# CC1314R10 register map
File version: 1.0
CPU: CM33 1.0, other endian, MPU, FPU, 3 interrupt priority bits
Registers are 32-bit, read-write, reset 0x0 unless marked. A register's access mark holds for its fields unless they carry their own. Offsets are from the block's base; [hi:lo] are bit positions; {n}, {i} and the like mark numbered series; <NAME> marks a mode.

## UART0 — Universal Asynchronous Receiver/Transmitter (UART) interface
Base 0x40001000
Same registers: UART1 0x4000B000, UART2 0x4000C000, UART3 0x4000D000
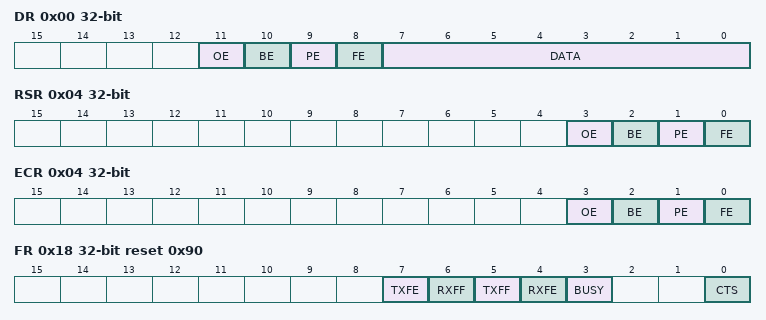
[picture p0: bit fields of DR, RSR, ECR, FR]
0x00 DR — Data For words to be transmitted: - if the FIFOs are enabled (LCRH.FEN = 1), data written to this location is pushed onto the transmit FIFO - if the FIFOs are not enabled (LCRH.FEN = 0), data is stored in the transmitter holding register (the bottom word of the transmit FIFO). The write operation initiates transmission from the UART. The data is prefixed with a start bit, appended with the appropriate parity bit (if parity is enabled), and a stop bit. The resultant word is then transmitted. For received words: - if the FIFOs are enabled (LCRH.FEN = 1), the data byte and the 4-bit status (break, frame, parity, and overrun) is pushed onto the 12-bit wide receive FIFO - if the FIFOs are not enabled (LCRH.FEN = 0), the data byte and status are stored in the receiving holding register (the bottom word of the receive FIFO). The received data byte is read by performing reads from this register along with the corresponding status information. The status information can also be read by a read of the RSR register.
  [11] OE ro — [11:11] UART Overrun Error: This bit is set to 1 if data is received and the receive FIFO is already full. The FIFO contents remain valid because no more data is written when the FIFO is full, , only the contents of the shift register are overwritten. This is cleared to 0 once there is an empty space in the FIFO and a new character can be written to it.
  [10] BE ro — [10:10] UART Break Error: This bit is set to 1 if a break condition was detected, indicating that the received data input (UARTRXD input pin) was held LOW for longer than a full-word transmission time (defined as start, data, parity and stop bits). In FIFO mode, this error is associated with the character at the top of the FIFO (that is., the oldest received data character since last read). When a break occurs, a 0 character is loaded into the FIFO. The next character is enabled after the receive data input (UARTRXD input pin) goes to a 1 (marking state), and the next valid start bit is received.
  [9] PE ro — [9:9] UART Parity Error: When set to 1, it indicates that the parity of the received data character does not match the parity that the LCRH.EPS and LCRH.SPS select. In FIFO mode, this error is associated with the character at the top of the FIFO (that is, the oldest received data character since last read).
  [8] FE ro — [8:8] UART Framing Error: When set to 1, it indicates that the received character did not have a valid stop bit (a valid stop bit is 1). In FIFO mode, this error is associated with the character at the top of the FIFO (that is., the oldest received data character since last read).
  [7:0] DATA — [7:0] Data transmitted or received: On writes, the transmit data character is pushed into the FIFO. On reads, the oldest received data character since the last read is returned.
0x04 RSR — Status This register is mapped to the same address as ECR register. Reads from this address are associated with RSR register and return the receive status. Writes to this address are associated with ECR register and clear the receive status flags (framing, parity, break, and overrun errors). If the status is read from this register, then the status information for break, framing and parity corresponds to the data character read from the Data Register, DR prior to reading the RSR. The status information for overrun is set immediately when an overrun condition occurs.
  [3] OE ro — [3:3] UART Overrun Error: This bit is set to 1 if data is received and the receive FIFO is already full. The FIFO contents remain valid because no more data is written when the FIFO is full, , only the contents of the shift register are overwritten. This is cleared to 0 once there is an empty space in the FIFO and a new character can be written to it.
  [2] BE ro — [2:2] UART Break Error: This bit is set to 1 if a break condition was detected, indicating that the received data input (UARTRXD input pin) was held LOW for longer than a full-word transmission time (defined as start, data, parity and stop bits). When a break occurs, a 0 character is loaded into the FIFO. The next character is enabled after the receive data input (UARTRXD input pin) goes to a 1 (marking state), and the next valid start bit is received.
  [1] PE ro — [1:1] UART Parity Error: When set to 1, it indicates that the parity of the received data character does not match the parity that the LCRH.EPS and LCRH.SPS select.
  [0] FE ro — [0:0] UART Framing Error: When set to 1, it indicates that the received character did not have a valid stop bit (a valid stop bit is 1).
0x04 ECR — Error Clear This register is mapped to the same address as RSR register. Reads from this address are associated with RSR register and return the receive status. Writes to this address are associated with ECR register and clear the receive status flags (framing, parity, break, and overrun errors).
  [3] OE wo — [3:3] The framing (FE), parity (PE), break (BE) and overrun (OE) errors are cleared to 0 by any write to this register.
  [2] BE wo — [2:2] The framing (FE), parity (PE), break (BE) and overrun (OE) errors are cleared to 0 by any write to this register.
  [1] PE wo — [1:1] The framing (FE), parity (PE), break (BE) and overrun (OE) errors are cleared to 0 by any write to this register.
  [0] FE wo — [0:0] The framing (FE), parity (PE), break (BE) and overrun (OE) errors are cleared to 0 by any write to this register.
0x18 FR reset 0x90 — Flag Reads from this register return the UART flags.
  [7] TXFE ro — [7:7] UART Transmit FIFO Empty: The meaning of this bit depends on the state of LCRH.FEN . - If the FIFO is disabled, this bit is set when the transmit holding register is empty. - If the FIFO is enabled, this bit is set when the transmit FIFO is empty. This bit does not indicate if there is data in the transmit shift register.
  [6] RXFF ro — [6:6] UART Receive FIFO Full: The meaning of this bit depends on the state of LCRH.FEN. - If the FIFO is disabled, this bit is set when the receive holding register is full. - If the FIFO is enabled, this bit is set when the receive FIFO is full.
  [5] TXFF ro — [5:5] UART Transmit FIFO Full: Transmit FIFO full. The meaning of this bit depends on the state of LCRH.FEN. - If the FIFO is disabled, this bit is set when the transmit holding register is full. - If the FIFO is enabled, this bit is set when the transmit FIFO is full.
  [4] RXFE ro — [4:4] UART Receive FIFO Empty: Receive FIFO empty. The meaning of this bit depends on the state of LCRH.FEN. - If the FIFO is disabled, this bit is set when the receive holding register is empty. - If the FIFO is enabled, this bit is set when the receive FIFO is empty.
  [3] BUSY ro — [3:3] UART Busy: If this bit is set to 1, the UART is busy transmitting data. This bit remains set until the complete byte, including all the stop bits, has been sent from the shift register. This bit is set as soon as the transmit FIFO becomes non-empty, regardless of whether the UART is enabled or not.
  [0] CTS ro — [0:0] Clear To Send: This bit is the complement of the active-low UART CTS input pin. That is, the bit is 1 when CTS input pin is LOW.
0x24 IBRD — Integer Baud-Rate Divisor If this register is modified while transmission or reception is on-going, the baud rate will not be updated until transmission or reception of the current character is complete.
  [15:0] DIVINT — [15:0] The integer baud rate divisor: The baud rate divisor is calculated using the formula below: Baud rate divisor = (UART reference clock frequency) / (16 * Baud rate) Baud rate divisor must be minimum 1 and maximum 65535. That is, DIVINT=0 does not give a valid baud rate. Similarly, if DIVINT=0xFFFF, any non-zero values in FBRD.DIVFRAC will be illegal. A valid value must be written to this field before the UART can be used for RX or TX operations.
0x28 FBRD — Fractional Baud-Rate Divisor If this register is modified while trasmission or reception is on-going, the baudrate will not be updated until transmission or reception of the current character is complete.
  [5:0] DIVFRAC — [5:0] Fractional Baud-Rate Divisor: The baud rate divisor is calculated using the formula below: Baud rate divisor = (UART reference clock frequency) / (16 * Baud rate) Baud rate divisor must be minimum 1 and maximum 65535. That is, IBRD.DIVINT=0 does not give a valid baud rate. Similarly, if IBRD.DIVINT=0xFFFF, any non-zero values in DIVFRAC will be illegal. A valid value must be written to this field before the UART can be used for RX or TX operations.
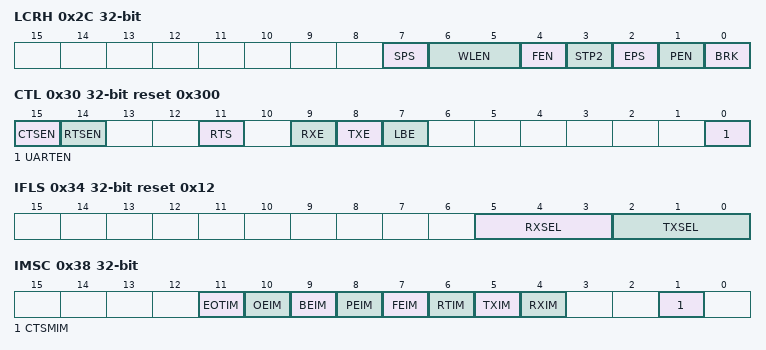
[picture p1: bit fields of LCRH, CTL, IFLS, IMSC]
0x2C LCRH — Line Control
  [7] SPS — [7:7] UART Stick Parity Select: 0: Stick parity is disabled 1: The parity bit is transmitted and checked as invert of EPS field (i.e. the parity bit is transmitted and checked as 1 when EPS = 0). This bit has no effect when PEN disables parity checking and generation.
  [6:5] WLEN — [6:5] UART Word Length: These bits indicate the number of data bits transmitted or received in a frame.
    {v}=Word Length {v+5} bits (v=0..3)
  [4] FEN — [4:4] UART Enable FIFOs
    1=EN (Transmit and receive FIFO buffers are enabled (FIFO mode)); 0=DIS (FIFOs are disabled (character mode) that is, the FIFOs become 1-byte-deep holding registers.)
  [3] STP2 — [3:3] UART Two Stop Bits Select: If this bit is set to 1, two stop bits are transmitted at the end of the frame. The receive logic does not check for two stop bits being received.
  [2] EPS — [2:2] UART Even Parity Select
    1=EVEN (Even parity: The UART generates or checks for an even number of 1s in the data and parity bits.); 0=ODD (Odd parity: The UART generates or checks for an odd number of 1s in the data and parity bits.)
  [1] PEN — [1:1] UART Parity Enable This bit controls generation and checking of parity bit.
    1=EN (Parity checking and generation is enabled.); 0=DIS (Parity is disabled and no parity bit is added to the data frame)
  [0] BRK — [0:0] UART Send Break If this bit is set to 1, a low-level is continually output on the UARTTXD output pin, after completing transmission of the current character. For the proper execution of the break command, the software must set this bit for at least two complete frames. For normal use, this bit must be cleared to 0.
0x30 CTL reset 0x300 — Control
  [15] CTSEN — [15:15] CTS hardware flow control enable
    1=EN (CTS hardware flow control enabled); 0=DIS (CTS hardware flow control disabled)
  [14] RTSEN — [14:14] RTS hardware flow control enable
    1=EN (RTS hardware flow control enabled); 0=DIS (RTS hardware flow control disabled)
  [11] RTS — [11:11] Request to Send This bit is the complement of the active-low UART RTS output. That is, when the bit is programmed to a 1 then RTS output on the pins is LOW.
  [9] RXE — [9:9] UART Receive Enable If the UART is disabled in the middle of reception, it completes the current character before stopping.
    1=EN (UART Receive enabled); 0=DIS (UART Receive disabled)
  [8] TXE — [8:8] UART Transmit Enable If the UART is disabled in the middle of transmission, it completes the current character before stopping.
    1=EN (UART Transmit enabled); 0=DIS (UART Transmit disabled)
  [7] LBE — [7:7] UART Loop Back Enable: Enabling the loop-back mode connects the UARTTXD output from the UART to UARTRXD input of the UART.
    1=EN (Loop Back enabled); 0=DIS (Loop Back disabled)
  [0] UARTEN — [0:0] UART Enable
    1=EN (UART enabled); 0=DIS (UART disabled)
0x34 IFLS reset 0x12 — Interrupt FIFO Level Select
  [5:3] RXSEL — [5:3] Receive interrupt FIFO level select: This field sets the trigger points for the receive interrupt. Values 0b101-0b111 are reserved.
    4=7_8 (Receive FIFO becomes >= 7/8 full); 3=6_8 (Receive FIFO becomes >= 3/4 full); 2=4_8 (Receive FIFO becomes >= 1/2 full); 1=2_8 (Receive FIFO becomes >= 1/4 full); 0=1_8 (Receive FIFO becomes >= 1/8 full)
  [2:0] TXSEL — [2:0] Transmit interrupt FIFO level select: This field sets the trigger points for the transmit interrupt. Values 0b101-0b111 are reserved.
    4=7_8 (Transmit FIFO becomes <= 7/8 full); 3=6_8 (Transmit FIFO becomes <= 3/4 full); 2=4_8 (Transmit FIFO becomes <= 1/2 full); 1=2_8 (Transmit FIFO becomes <= 1/4 full); 0=1_8 (Transmit FIFO becomes <= 1/8 full)
0x38 IMSC — Interrupt Mask Set/Clear
  [11] EOTIM — [11:11] End of Transmission interrupt mask. A read returns the current mask for UART's EoT interrupt. On a write of 1, the mask of the EoT interrupt is set which means the interrupt state will be reflected in MIS.EOTMIS. A write of 0 clears the mask which means MIS.EOTMIS will not reflect the interrupt.
  [10] OEIM — [10:10] Overrun error interrupt mask. A read returns the current mask for UART's overrun error interrupt. On a write of 1, the mask of the overrun error interrupt is set which means the interrupt state will be reflected in MIS.OEMIS. A write of 0 clears the mask which means MIS.OEMIS will not reflect the interrupt.
  [9] BEIM — [9:9] Break error interrupt mask. A read returns the current mask for UART's break error interrupt. On a write of 1, the mask of the overrun error interrupt is set which means the interrupt state will be reflected in MIS.BEMIS. A write of 0 clears the mask which means MIS.BEMIS will not reflect the interrupt.
  [8] PEIM — [8:8] Parity error interrupt mask. A read returns the current mask for UART's parity error interrupt. On a write of 1, the mask of the overrun error interrupt is set which means the interrupt state will be reflected in MIS.PEMIS. A write of 0 clears the mask which means MIS.PEMIS will not reflect the interrupt.
  [7] FEIM — [7:7] Framing error interrupt mask. A read returns the current mask for UART's framing error interrupt. On a write of 1, the mask of the overrun error interrupt is set which means the interrupt state will be reflected in MIS.FEMIS. A write of 0 clears the mask which means MIS.FEMIS will not reflect the interrupt.
  [6] RTIM — [6:6] Receive timeout interrupt mask. A read returns the current mask for UART's receive timeout interrupt. On a write of 1, the mask of the overrun error interrupt is set which means the interrupt state will be reflected in MIS.RTMIS. A write of 0 clears the mask which means this bitfield will not reflect the interrupt. The raw interrupt for receive timeout RIS.RTRIS cannot be set unless the mask is set (RTIM = 1). This is because the mask acts as an enable for power saving. That is, the same status can be read from MIS.RTMIS and RIS.RTRIS.
  [5] TXIM — [5:5] Transmit interrupt mask. A read returns the current mask for UART's transmit interrupt. On a write of 1, the mask of the overrun error interrupt is set which means the interrupt state will be reflected in MIS.TXMIS. A write of 0 clears the mask which means MIS.TXMIS will not reflect the interrupt.
  [4] RXIM — [4:4] Receive interrupt mask. A read returns the current mask for UART's receive interrupt. On a write of 1, the mask of the overrun error interrupt is set which means the interrupt state will be reflected in MIS.RXMIS. A write of 0 clears the mask which means MIS.RXMIS will not reflect the interrupt.
  [1] CTSMIM — [1:1] Clear to Send (CTS) modem interrupt mask. A read returns the current mask for UART's clear to send interrupt. On a write of 1, the mask of the overrun error interrupt is set which means the interrupt state will be reflected in MIS.CTSMMIS. A write of 0 clears the mask which means MIS.CTSMMIS will not reflect the interrupt.
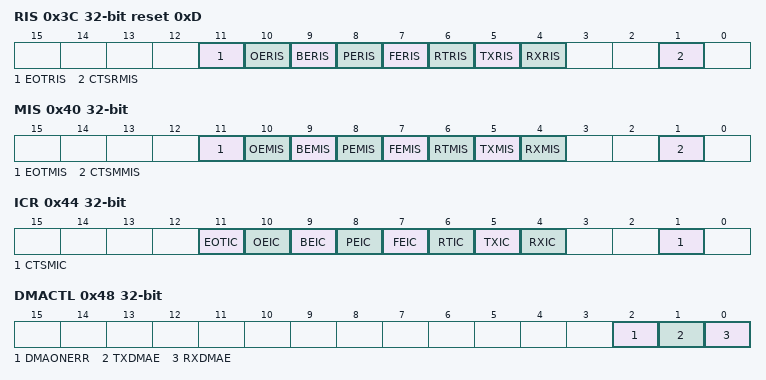
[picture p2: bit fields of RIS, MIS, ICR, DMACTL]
0x3C RIS reset 0xD — Raw Interrupt Status
  [11] EOTRIS ro — [11:11] End of Transmission interrupt status: This field returns the raw interrupt state of UART's end of transmission interrupt. End of transmission flag is set when all the Transmit data in the FIFO and on the TX Line is tranmitted.
  [10] OERIS ro — [10:10] Overrun error interrupt status: This field returns the raw interrupt state of UART's overrun error interrupt. Overrun error occurs if data is received and the receive FIFO is full.
  [9] BERIS ro — [9:9] Break error interrupt status: This field returns the raw interrupt state of UART's break error interrupt. Break error is set when a break condition is detected, indicating that the received data input (UARTRXD input pin) was held LOW for longer than a full-word transmission time (defined as start, data, parity and stop bits).
  [8] PERIS ro — [8:8] Parity error interrupt status: This field returns the raw interrupt state of UART's parity error interrupt. Parity error is set if the parity of the received data character does not match the parity that the LCRH.EPS and LCRH.SPS select.
  [7] FERIS ro — [7:7] Framing error interrupt status: This field returns the raw interrupt state of UART's framing error interrupt. Framing error is set if the received character does not have a valid stop bit (a valid stop bit is 1).
  [6] RTRIS ro — [6:6] Receive timeout interrupt status: This field returns the raw interrupt state of UART's receive timeout interrupt. The receive timeout interrupt is asserted when the receive FIFO is not empty, and no more data is received during a 32-bit period. The receive timeout interrupt is cleared either when the FIFO becomes empty through reading all the data, or when a 1 is written to ICR.RTIC. The raw interrupt for receive timeout cannot be set unless the mask is set (IMSC.RTIM = 1). This is because the mask acts as an enable for power saving. That is, the same status can be read from MIS.RTMIS and RTRIS.
  [5] TXRIS ro — [5:5] Transmit interrupt status: This field returns the raw interrupt state of UART's transmit interrupt. When FIFOs are enabled (LCRH.FEN = 1), the transmit interrupt is asserted if the number of bytes in transmit FIFO is equal to or lower than the programmed trigger level (IFLS.TXSEL). The transmit interrupt is cleared by writing data to the transmit FIFO until it becomes greater than the trigger level, or by clearing the interrupt through ICR.TXIC. When FIFOs are disabled (LCRH.FEN = 0), that is they have a depth of one location, the transmit interrupt is asserted if there is no data present in the transmitters single location. It is cleared by performing a single write to the transmit FIFO, or by clearing the interrupt through ICR.TXIC.
  [4] RXRIS ro — [4:4] Receive interrupt status: This field returns the raw interrupt state of UART's receive interrupt. When FIFOs are enabled (LCRH.FEN = 1), the receive interrupt is asserted if the receive FIFO reaches the programmed trigger level (IFLS.RXSEL). The receive interrupt is cleared by reading data from the receive FIFO until it becomes less than the trigger level, or by clearing the interrupt through ICR.RXIC. When FIFOs are disabled (LCRH.FEN = 0), that is they have a depth of one location, the receive interrupt is asserted if data is received thereby filling the location. The receive interrupt is cleared by performing a single read of the receive FIFO, or by clearing the interrupt through ICR.RXIC.
  [1] CTSRMIS ro — [1:1] Clear to Send (CTS) modem interrupt status: This field returns the raw interrupt state of UART's clear to send interrupt.
0x40 MIS — Masked Interrupt Status
  [11] EOTMIS ro — [11:11] End of Transmission interrupt status: This field returns the masked interrupt state of the overrun interrupt which is the AND product of raw interrupt state RIS.EOTRIS and the mask setting IMSC.EOTIM.
  [10] OEMIS ro — [10:10] Overrun error masked interrupt status: This field returns the masked interrupt state of the overrun interrupt which is the AND product of raw interrupt state RIS.OERIS and the mask setting IMSC.OEIM.
  [9] BEMIS ro — [9:9] Break error masked interrupt status: This field returns the masked interrupt state of the break error interrupt which is the AND product of raw interrupt state RIS.BERIS and the mask setting IMSC.BEIM.
  [8] PEMIS ro — [8:8] Parity error masked interrupt status: This field returns the masked interrupt state of the parity error interrupt which is the AND product of raw interrupt state RIS.PERIS and the mask setting IMSC.PEIM.
  [7] FEMIS ro — [7:7] Framing error masked interrupt status: Returns the masked interrupt state of the framing error interrupt which is the AND product of raw interrupt state RIS.FERIS and the mask setting IMSC.FEIM.
  [6] RTMIS ro — [6:6] Receive timeout masked interrupt status: Returns the masked interrupt state of the receive timeout interrupt. The raw interrupt for receive timeout cannot be set unless the mask is set (IMSC.RTIM = 1). This is because the mask acts as an enable for power saving. That is, the same status can be read from RTMIS and RIS.RTRIS.
  [5] TXMIS ro — [5:5] Transmit masked interrupt status: This field returns the masked interrupt state of the transmit interrupt which is the AND product of raw interrupt state RIS.TXRIS and the mask setting IMSC.TXIM.
  [4] RXMIS ro — [4:4] Receive masked interrupt status: This field returns the masked interrupt state of the receive interrupt which is the AND product of raw interrupt state RIS.RXRIS and the mask setting IMSC.RXIM.
  [1] CTSMMIS ro — [1:1] Clear to Send (CTS) modem masked interrupt status: This field returns the masked interrupt state of the clear to send interrupt which is the AND product of raw interrupt state RIS.CTSRMIS and the mask setting IMSC.CTSMIM.
0x44 ICR — Interrupt Clear On a write of 1, the corresponding interrupt is cleared. A write of 0 has no effect.
  [11] EOTIC wo — [11:11] End of Transmission interrupt clear: Writing 1 to this field clears the overrun error interrupt (RIS.EOTRIS). Writing 0 has no effect.
  [10] OEIC wo — [10:10] Overrun error interrupt clear: Writing 1 to this field clears the overrun error interrupt (RIS.OERIS). Writing 0 has no effect.
  [9] BEIC wo — [9:9] Break error interrupt clear: Writing 1 to this field clears the break error interrupt (RIS.BERIS). Writing 0 has no effect.
  [8] PEIC wo — [8:8] Parity error interrupt clear: Writing 1 to this field clears the parity error interrupt (RIS.PERIS). Writing 0 has no effect.
  [7] FEIC wo — [7:7] Framing error interrupt clear: Writing 1 to this field clears the framing error interrupt (RIS.FERIS). Writing 0 has no effect.
  [6] RTIC wo — [6:6] Receive timeout interrupt clear: Writing 1 to this field clears the receive timeout interrupt (RIS.RTRIS). Writing 0 has no effect.
  [5] TXIC wo — [5:5] Transmit interrupt clear: Writing 1 to this field clears the transmit interrupt (RIS.TXRIS). Writing 0 has no effect.
  [4] RXIC wo — [4:4] Receive interrupt clear: Writing 1 to this field clears the receive interrupt (RIS.RXRIS). Writing 0 has no effect.
  [1] CTSMIC wo — [1:1] Clear to Send (CTS) modem interrupt clear: Writing 1 to this field clears the clear to send interrupt (RIS.CTSRMIS). Writing 0 has no effect.
0x48 DMACTL — DMA Control
  [2] DMAONERR — [2:2] DMA on error. If this bit is set to 1, the DMA receive request outputs (for single and burst requests) are disabled when the UART error interrupt is asserted (more specifically if any of the error interrupts RIS.PERIS, RIS.BERIS, RIS.FERIS or RIS.OERIS are asserted).
  [1] TXDMAE — [1:1] Transmit DMA enable. If this bit is set to 1, DMA for the transmit FIFO is enabled.
  [0] RXDMAE — [0:0] Receive DMA enable. If this bit is set to 1, DMA for the receive FIFO is enabled.
